# cslr_vpss_001 register map
Vendor: Texas Instruments
Peripheral module from a debugger description file.
Registers are 32-bit, read-only, reset 0x0 unless marked. A register's access mark holds for its fields unless they carry their own. Offsets are as the file gives them; lines under a group give offsets from that group; [hi:lo] are bit positions; {n}, {i} and the like mark numbered series; 'fields as' and 'values as' point back to an identical list; <NAME> marks a mode.

## VPSS — Video Processing Subsystem - read-only status registers (spec version: 1.00.w.11)
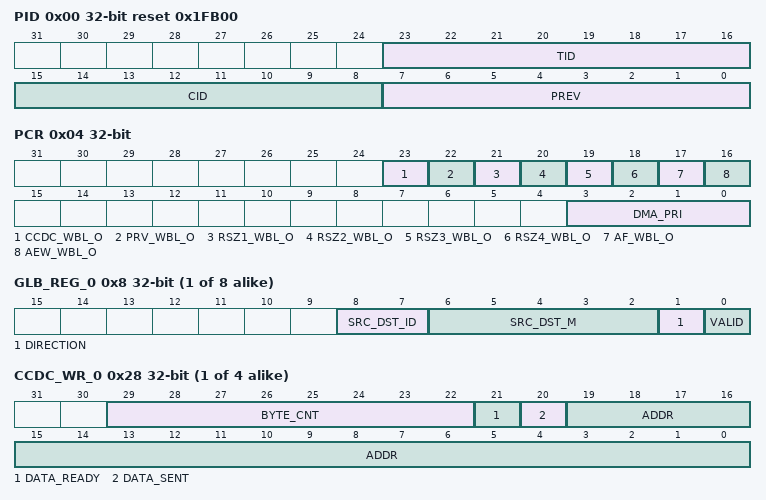
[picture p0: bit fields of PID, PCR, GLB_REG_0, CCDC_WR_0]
0x00 PID reset 0x1FB00 — Peripheral Revision and Class Information
  [23:16] TID — Peripheral Identificiation VPSS
  [15:8] CID — Class Identification VPSS
  [7:0] PREV — Peripheral Revision Number Initial Revision
0x04 PCR access per field — VPSS Control Register
  [23] CCDC_WBL_O rw — Write buffer memory overflow (CCDC) All data units have been filled and not yet transferred to SDRAM before the next data unit is to be filled from the WBL. Software has to clear the bit.
    0=NOOVERFLOW; 1=OVERFLOW (overflow (fail))
  [22] PRV_WBL_O rw — Write buffer memory overflow (Preview engine) All data units have been filled and not yet transferred to SDRAM before the next data unit is to be filled from the WBL. Software has to clear the bit.
    0=NOOVERFLOW; 1=OVERFLOW (overflow (fail))
  [22-n] RSZ{n}_WBL_O rw (n=1..4) — Write buffer memory overflow (Resizer line {n}) All data units have been filled and not yet transferred to SDRAM before the next data unit is to be filled from the WBL. Software has to clear the bit.
    0=NOOVERFLOW; 1=OVERFLOW (overflow (fail))
  [17] AF_WBL_O rw — Write buffer memory overflow (AF) All data units have been filled and not yet transferred to SDRAM before the next data unit is to be filled from the WBL. Software has to clear the bit.
    0=NOOVERFLOW; 1=OVERFLOW (overflow (fail))
  [16] AEW_WBL_O rw — Write buffer memory overflow (AE/AWB) All data units have been filled and not yet transferred to SDRAM before the next data unit is to be filled from the WBL. Software has to clear the bit.
    0=NOOVERFLOW; 1=OVERFLOW (overflow (fail))
  [3:0] DMA_PRI rw — VBUSM priority in the system (to the DDR EMIF) The default should be the highest priority in the system
{0x8+4i} GLB_REG_{i} (i=0..7) — Global register {i}
  [8:7] SRC_DST_ID — Individual module register command number Note that for the modules that only have 2 individual requestors, this field will only display either 0 or 1. For modules that have 4 individual requestors, this field will display 0 or 1 or 2 or 3.
    {v}=RW_REQ_{v+1} (Read/write module requestor #{v+1}) (v=0..3)
  [6:2] SRC_DST_M — Source or Destination Module
    0=CCDC_OUT (CCDC output); 1=CCDC_FAULTPIX_IN (CCDC fault pixel correction input); 2=PREV_IN (preview engine input); 3=PREV_OUT (preview engine output); 4=PREV_DKFRM_IN (preview engine dark frame subtract input); 5=RESZ_IN (resizer input); {v}=RESZ_OUT_{v-5} (resizer output line #{v-5}) (v=6..9); 11=H3A_AF_OUT (h3A output (AF)); 12=H3A_AE_AWB_OUT (h3A output (AE/AWB)); 13=OSD_VIDWIN_0 (OSD video window #0); 14=OSD_VIDWIN_1 (OSD video window #1); 15=OSD_BMPWIN_0 (OSD overlay/graphic window #0); 16=OSD_BMPWIN_1 (OSD overlay/graphic window #1)
  [1] DIRECTION
    0=READ; 1=WRITE
  [0] VALID — Valid bit
    0=NOTVALID; 1=VALID
{0x28+4i} CCDC_WR_{i} (i=0..3) — CCDC output write request #{i+1}
  [29:22] BYTE_CNT — Current byte count
  [21] DATA_READY — Data ready (block of data confirmed by the module)
    0=NO; 1=YES
  [20] DATA_SENT — Data send to the destination, waiting for status
    0=NO; 1=YES
  [19:0] ADDR — Upper 20-bits of the write address
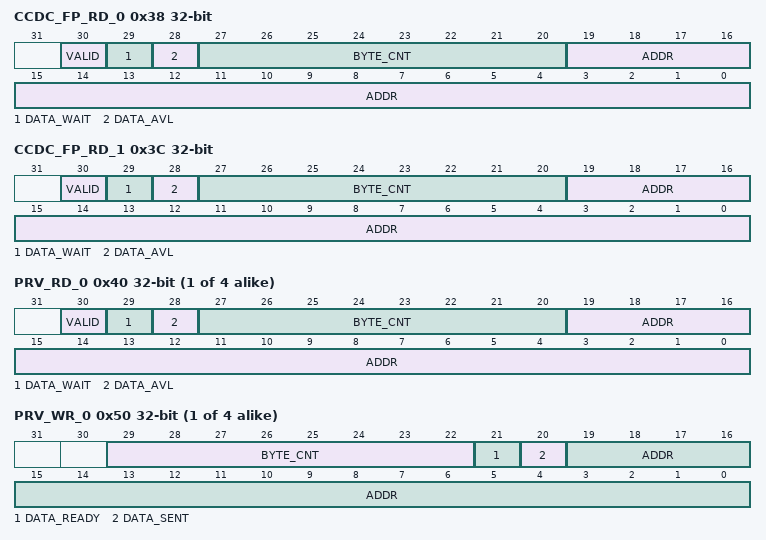
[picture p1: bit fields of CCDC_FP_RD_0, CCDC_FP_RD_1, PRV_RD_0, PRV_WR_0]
0x38 CCDC_FP_RD_0 — CCDC fault pixel correction read request #1
  [30] VALID — Valid bit
    0=NOTVALID; 1=VALID
  [29] DATA_WAIT — Waiting for data (command already accepted)
    0=NO; 1=YES
  [28] DATA_AVL — Data available (received from source and can be read by the module)
    0=NO; 1=YES
  [27:20] BYTE_CNT — Byte count requested
  [19:0] ADDR — Upper 20-bits of the read address
0x3C CCDC_FP_RD_1 — CCDC fault pixel correction read request #1
  fields as CCDC_FP_RD_0
{0x40+4i} PRV_RD_{i} (i=0..3) — Preview engine read request #{i+1}
  fields as CCDC_FP_RD_0
{0x50+4i} PRV_WR_{i} (i=0..3) — Preview engine write request #{i+1}
  fields as CCDC_WR_0
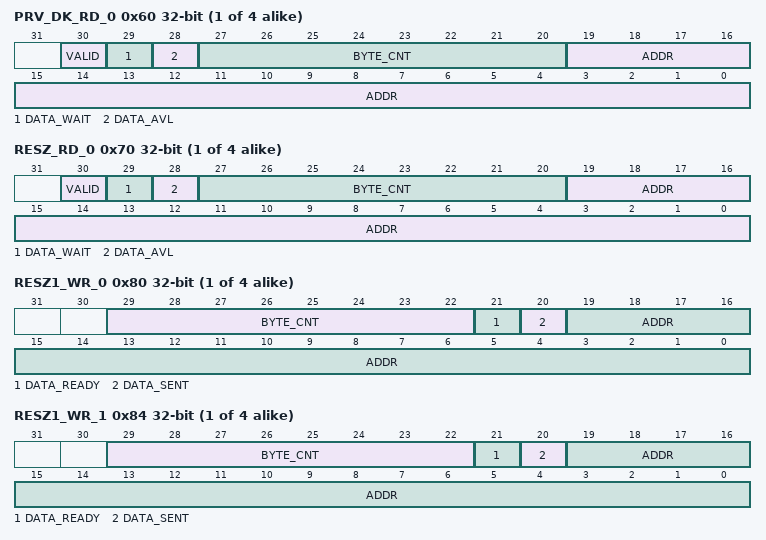
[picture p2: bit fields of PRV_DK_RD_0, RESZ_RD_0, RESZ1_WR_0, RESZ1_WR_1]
{0x60+4i} PRV_DK_RD_{i} (i=0..3) — Preview engine dark frame read request #{i+1}
  [30] VALID — Valid bit
    0=NOTVALID; 1=VALID
  [29] DATA_WAIT — Waiting for data (command already accepted)
    0=NO; 1=YES
  [28] DATA_AVL — Data available (received from source and can be read by the module)\
    0=NO; 1=YES
  [27:20] BYTE_CNT — Byte count requested
  [19:0] ADDR — Upper 20-bits of the read address
{0x70+4i} RESZ_RD_{i} (i=0..3) — Resizer read request #{i+1}
  fields as PRV_DK_RD_0
{0x70+0x10*i} RESZ{i}_WR_0 (i=1..4) — Resizer line#{i} output write request #1
  fields as CCDC_WR_0
{0x74+0x10*i} RESZ{i}_WR_1 (i=1..4) — Resizer line#{i} output write request #2
  fields as CCDC_WR_0
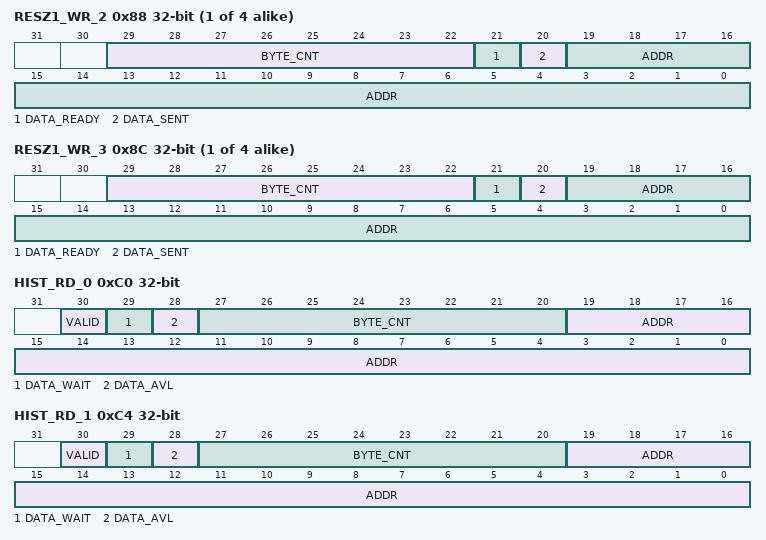
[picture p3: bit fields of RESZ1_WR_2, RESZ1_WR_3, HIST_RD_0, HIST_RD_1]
{0x78+0x10*i} RESZ{i}_WR_2 (i=1..4) — Resizer line#{i} output write request #3
  fields as CCDC_WR_0
{0x7C+0x10*i} RESZ{i}_WR_3 (i=1..4) — Resizer line#{i} output write request #4
  fields as CCDC_WR_0
0xC0 HIST_RD_0 — Histogram read request #1
  [30] VALID — Valid bit
    0=NOTVALID; 1=VALID
  [29] DATA_WAIT — Data ready (block of data confirmed by the module)
    0=NO; 1=YES
  [28] DATA_AVL — Data send to the destination, waiting for status
    0=NO; 1=YES
  [27:20] BYTE_CNT — Byte count requested
  [19:0] ADDR — Upper 20-bits of the read address
0xC4 HIST_RD_1 — Histogram read request #2
  fields as HIST_RD_0
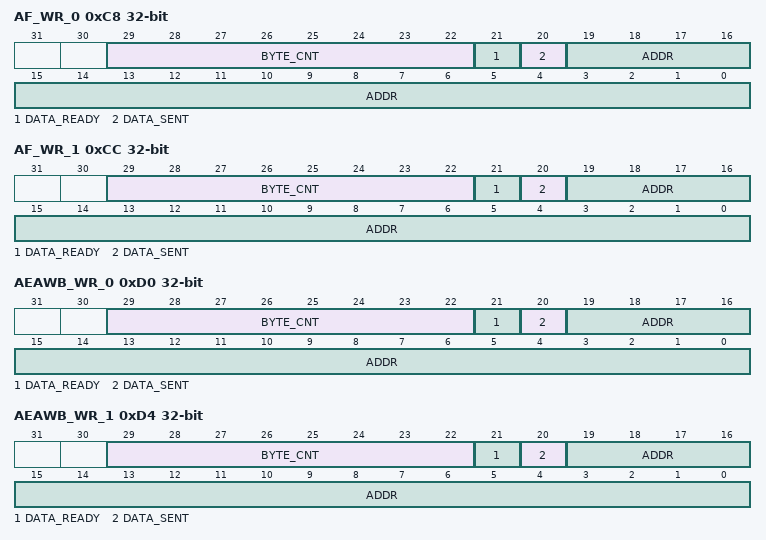
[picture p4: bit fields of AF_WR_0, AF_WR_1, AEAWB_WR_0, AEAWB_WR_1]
0xC8 AF_WR_0 — Auto Focus write request #1
  fields as CCDC_WR_0
0xCC AF_WR_1 — Auto Focus write request #2
  fields as CCDC_WR_0
0xD0 AEAWB_WR_0 — AE/AWB write request #1
  fields as CCDC_WR_0
0xD4 AEAWB_WR_1 — AE/AWB write request #2
  fields as CCDC_WR_0
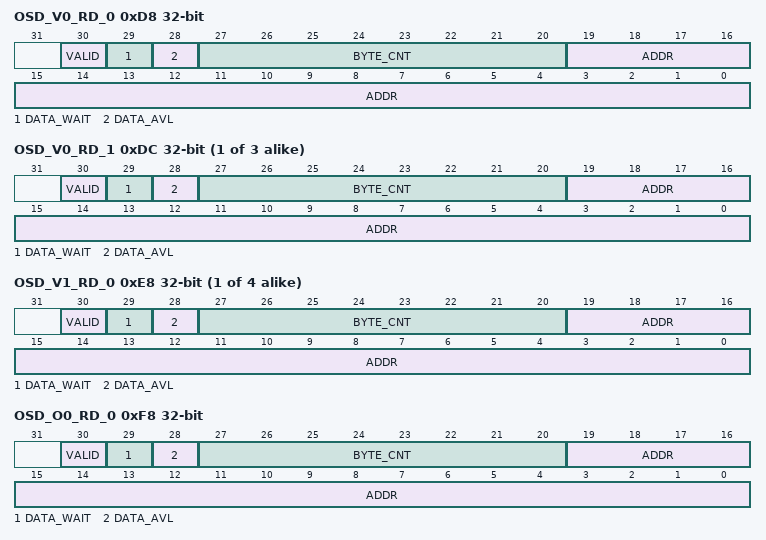
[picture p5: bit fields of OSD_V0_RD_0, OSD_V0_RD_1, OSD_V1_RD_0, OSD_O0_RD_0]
0xD8 OSD_V0_RD_0 — OSD video window 0 read request #1
  fields as HIST_RD_0
{0xD8+4i} OSD_V0_RD_{i} (i=1..3) — OSD video window 0 read request #{i+1}
  fields as CCDC_FP_RD_0
{0xE8+4i} OSD_V1_RD_{i} (i=0..3) — OSD video window 1 read request #{i+1}
  fields as CCDC_FP_RD_0
0xF8 OSD_O0_RD_0 — OSD graphics window 0 read request #1
  fields as CCDC_FP_RD_0
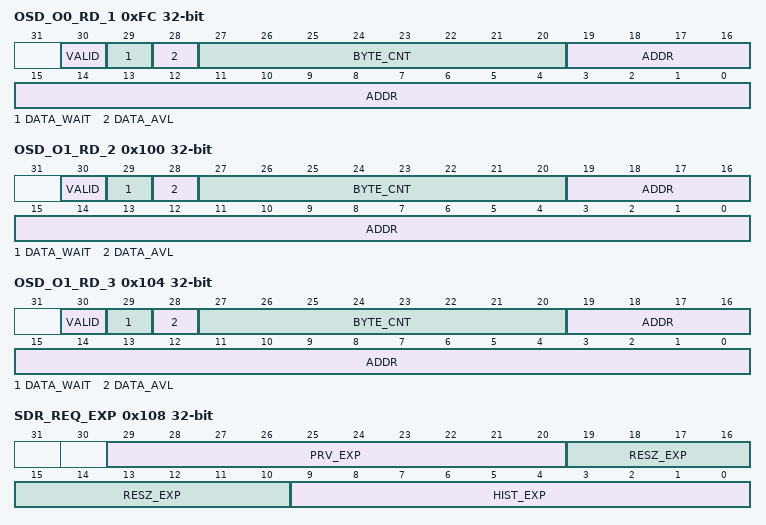
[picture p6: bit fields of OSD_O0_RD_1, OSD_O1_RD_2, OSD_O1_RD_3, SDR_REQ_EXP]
0xFC OSD_O0_RD_1 — OSD graphics window 0 read request #2
  fields as CCDC_FP_RD_0
0x100 OSD_O1_RD_2 — OSD graphics window 1 read request #1
  fields as CCDC_FP_RD_0
0x104 OSD_O1_RD_3 — OSD graphics window 1 read request #2
  fields as CCDC_FP_RD_0
0x108 SDR_REQ_EXP access per field — SDRAM non real-time read request expand
  [29:20] PRV_EXP rw — Preview engine read request expand The number of clock cycles (150 MHz in normal mode) to allow between two consecutive read requests from the module. This is for non real-time reads and spreading them with respect to the other traffic in the system thereby allowing lesser priority requests in the system to not be locked out during the duration of a frame being read from SDRAM
  [19:10] RESZ_EXP rw — Resizer read request expand The number of clock cycles (150 MHz in normal mode) to allow between two consecutive read requests from the module. This is for non real-time reads and spreading them with respect to the other traffic in the system thereby allowing lesser priority requests in the system to not be locked out during the duration of a frame being read from SDRAM
  [9:0] HIST_EXP rw — Histogram read request expand The number of clock cycles (150 MHz in normal mode) to allow between two consecutive read requests from the module. This is for non real-time reads and spreading them with respect to the other traffic in the system thereby allowing lesser priority requests in the system to not be locked out during the duration of a frame being read from SDRAM
